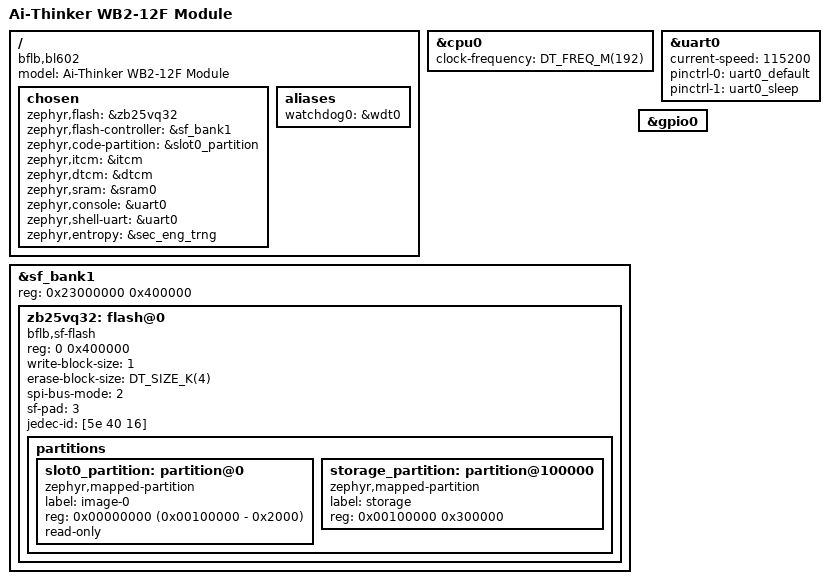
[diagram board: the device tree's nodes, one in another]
/*
 * Copyright (c) 2025 MASSDRIVER EI (massdriver.space)
 *
 * SPDX-License-Identifier: Apache-2.0
 */

#include <bflb/bl602.dtsi>
#include "ai_wb2_12f-pinctrl.dtsi"

/ {
	model = "Ai-Thinker WB2-12F Module";
	compatible = "bflb,bl602";

	chosen {
		zephyr,flash = &zb25vq32;
		zephyr,flash-controller = &sf_bank1;
		zephyr,code-partition = &slot0_partition;
		zephyr,itcm = &itcm;
		zephyr,dtcm = &dtcm;
		zephyr,sram = &sram0;
		zephyr,console = &uart0;
		zephyr,shell-uart = &uart0;
		zephyr,entropy = &sec_eng_trng;
	};

	aliases {
		watchdog0 = &wdt0;
	};
};

&cpu0 {
	clock-frequency = <DT_FREQ_M(192)>;
};

&sf_bank1 {
	reg = <0x23000000 0x400000>;
	ranges = <0x0 0x23000000 0x400000>;

	zb25vq32: flash@0 {
		compatible = "bflb,sf-flash", "soc-nv-flash";
		reg = <0 0x400000>;
		write-block-size = <1>;
		erase-block-size = <DT_SIZE_K(4)>;

		spi-bus-mode = <2>;
		sf-pad = <3>;
		jedec-id = [5e 40 16];

		partitions {
			#address-cells = <1>;
			#size-cells = <1>;

			slot0_partition: partition@0 {
				compatible = "zephyr,mapped-partition";
				label = "image-0";
				reg = <0x00000000 (0x00100000 - 0x2000)>;
				read-only;
			};

			storage_partition: partition@100000 {
				compatible = "zephyr,mapped-partition";
				label = "storage";
				reg = <0x00100000 0x300000>;
			};
		};
	};
};

&uart0 {
	status = "okay";
	current-speed = <115200>;

	pinctrl-0 = <&uart0_default>;
	pinctrl-1 = <&uart0_sleep>;
	pinctrl-names = "default", "sleep";
};

&gpio0 {
	status = "okay";
};
